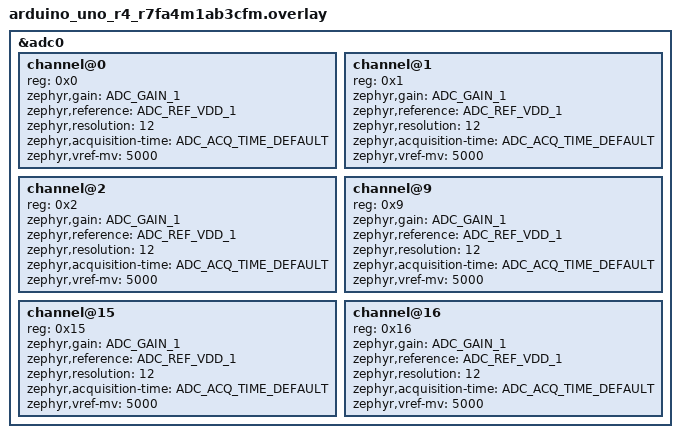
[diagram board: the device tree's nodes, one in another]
/*
 * Copyright (c) 2026 TOKITA Hiroshi
 *
 * SPDX-License-Identifier: Apache-2.0
 */

#include <zephyr/dt-bindings/adc/adc.h>

&adc0 {
	status = "okay";
	#address-cells = <1>;
	#size-cells = <0>;

	channel@0 {
		reg = <0x0>;
		zephyr,gain = "ADC_GAIN_1";
		zephyr,reference = "ADC_REF_VDD_1";
		zephyr,resolution = <12>;
		zephyr,acquisition-time = <ADC_ACQ_TIME_DEFAULT>;
		zephyr,vref-mv = <5000>;
	};

	channel@1 {
		reg = <0x1>;
		zephyr,gain = "ADC_GAIN_1";
		zephyr,reference = "ADC_REF_VDD_1";
		zephyr,resolution = <12>;
		zephyr,acquisition-time = <ADC_ACQ_TIME_DEFAULT>;
		zephyr,vref-mv = <5000>;
	};

	channel@2 {
		reg = <0x2>;
		zephyr,gain = "ADC_GAIN_1";
		zephyr,reference = "ADC_REF_VDD_1";
		zephyr,resolution = <12>;
		zephyr,acquisition-time = <ADC_ACQ_TIME_DEFAULT>;
		zephyr,vref-mv = <5000>;
	};

	channel@9 {
		reg = <0x9>;
		zephyr,gain = "ADC_GAIN_1";
		zephyr,reference = "ADC_REF_VDD_1";
		zephyr,resolution = <12>;
		zephyr,acquisition-time = <ADC_ACQ_TIME_DEFAULT>;
		zephyr,vref-mv = <5000>;
	};

	channel@15 {
		reg = <0x15>;
		zephyr,gain = "ADC_GAIN_1";
		zephyr,reference = "ADC_REF_VDD_1";
		zephyr,resolution = <12>;
		zephyr,acquisition-time = <ADC_ACQ_TIME_DEFAULT>;
		zephyr,vref-mv = <5000>;
	};

	channel@16 {
		reg = <0x16>;
		zephyr,gain = "ADC_GAIN_1";
		zephyr,reference = "ADC_REF_VDD_1";
		zephyr,resolution = <12>;
		zephyr,acquisition-time = <ADC_ACQ_TIME_DEFAULT>;
		zephyr,vref-mv = <5000>;
	};
};
